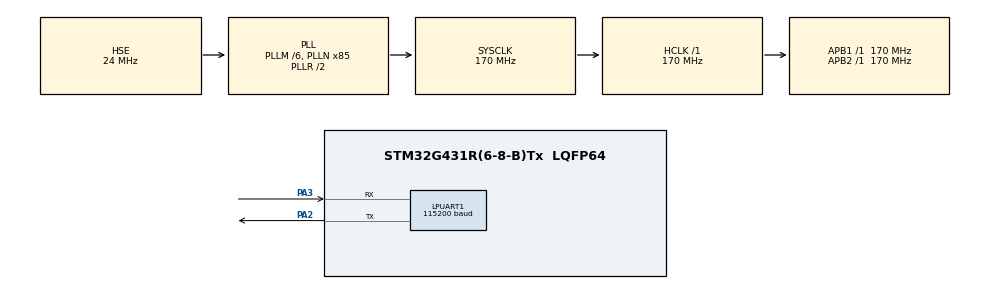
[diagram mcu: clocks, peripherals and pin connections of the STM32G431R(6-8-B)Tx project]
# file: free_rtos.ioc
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FREERTOS.Tasks01=defaultTask,0,128,StartDefaultTask,Default,NULL,Dynamic,NULL,NULL
FREERTOS.configENABLE_FPU=1
FREERTOS.configMAX_PRIORITIES=31
FREERTOS.configTOTAL_HEAP_SIZE=10240
FREERTOS.configUSE_NEWLIB_REENTRANT=1
LPUART1.BaudRate=115200
Mcu.Family=STM32G4
Mcu.Name=STM32G431R(6-8-B)Tx
Mcu.Package=LQFP64
NVIC.LPUART1_IRQn=true\:5\:0\:false\:false\:true\:true\:true\:true\:true
NVIC.PriorityGroup=NVIC_PRIORITYGROUP_4
NVIC.TIM1_UP_TIM16_IRQn=true\:15\:0\:false\:false\:true\:false\:false\:true\:true
NVIC.TimeBase=TIM1_UP_TIM16_IRQn
NVIC.TimeBaseIP=TIM1
PA13.Mode=Serial_Wire
PA13.Signal=SYS_JTMS-SWDIO
PA14.Mode=Serial_Wire
PA14.Signal=SYS_JTCK-SWCLK
PA2.Mode=Asynchronous
PA2.Signal=LPUART1_TX
PA3.Mode=Asynchronous
PA3.Signal=LPUART1_RX
PF0-OSC_IN.Mode=HSE-External-Oscillator
PF0-OSC_IN.Signal=RCC_OSC_IN
PF1-OSC_OUT.Mode=HSE-External-Oscillator
PF1-OSC_OUT.Signal=RCC_OSC_OUT
ProjectManager.HeapSize=0x200
ProjectManager.StackSize=0x400
ProjectManager.TargetToolchain=STM32CubeIDE
RCC.ADC12Freq_Value=170000000
RCC.AHBFreq_Value=170000000
RCC.APB1Freq_Value=170000000
RCC.APB1TimFreq_Value=170000000
RCC.APB2Freq_Value=170000000
RCC.APB2TimFreq_Value=170000000
RCC.CortexFreq_Value=170000000
RCC.EXTERNAL_CLOCK_VALUE=12288000
RCC.HCLKFreq_Value=170000000
RCC.HSE_VALUE=24000000
RCC.HSI48_VALUE=48000000
RCC.HSI_VALUE=16000000
RCC.LSE_VALUE=32768
RCC.PLLM=RCC_PLLM_DIV6
RCC.PLLN=85
RCC.PLLSourceVirtual=RCC_PLLSOURCE_HSE
RCC.SYSCLKFreq_VALUE=170000000
RCC.SYSCLKSource=RCC_SYSCLKSOURCE_PLLCLK
RCC.USBFreq_Value=170000000
RCC.VCOOutputFreq_Value=340000000
VP_FREERTOS_VS_CMSIS_V1.Mode=CMSIS_V1
VP_SYS_VS_tim1.Mode=TIM1
board=custom

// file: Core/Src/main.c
/* USER CODE BEGIN Header */
/**
  ******************************************************************************
  * @file           : main.c
  * @brief          : Main program body
  ******************************************************************************
  * @attention
  *
  * Copyright (c) 2023 STMicroelectronics.
  * All rights reserved.
  *
  * This software is licensed under terms that can be found in the LICENSE file
  * in the root directory of this software component.
  * If no LICENSE file comes with this software, it is provided AS-IS.
  *
  ******************************************************************************
  */
/* USER CODE END Header */
#include "main.h"
#include "cmsis_os.h"

UART_HandleTypeDef hlpuart1;

osThreadId defaultTaskHandle;

void SystemClock_Config(void);
static void MX_GPIO_Init(void);
static void MX_LPUART1_UART_Init(void);
void StartDefaultTask(void const * argument);

/* USER CODE BEGIN PFP */
SemaphoreHandle_t LPUARTMutex;
/* USER CODE END PFP */

/* USER CODE BEGIN 0 */

static void serialTask1(void *param) {
	uint32_t count = 0;

	for(;;) {
		if(xSemaphoreTake(LPUARTMutex, portMAX_DELAY) == pdTRUE) {
			HAL_UART_Transmit_IT(&hlpuart1, (uint8_t *)"Teste de Serial 1\n\r", 19);
			xSemaphoreGive(LPUARTMutex);
			count++;
		}

		portYIELD();
	}
}

static void serialTask2(void *param) {
	uint32_t count = 0;

	for(;;) {
		if(xSemaphoreTake(LPUARTMutex, portMAX_DELAY) == pdTRUE) {
			HAL_UART_Transmit_IT(&hlpuart1, (uint8_t *)"Teste de Serial 2\n\r", 19);
			xSemaphoreGive(LPUARTMutex);
			count++;
		}

		portYIELD();
	}
}

static void CPURemain(void *param) {
	uint32_t count = 0;

	for(;;) {
		count++;
	}
}

/* USER CODE END 0 */

int main(void)
{

  /* MCU Configuration--------------------------------------------------------*/

  /* Reset of all peripherals, Initializes the Flash interface and the Systick. */
  HAL_Init();

  /* Configure the system clock */
  SystemClock_Config();

  /* Initialize all configured peripherals */
  MX_GPIO_Init();
  MX_LPUART1_UART_Init();

  /* USER CODE BEGIN RTOS_MUTEX */
  /* add mutexes, ... */
  LPUARTMutex = xSemaphoreCreateMutex();
  /* USER CODE END RTOS_MUTEX */

  /* Create the thread(s) */
  /* definition and creation of defaultTask */
  osThreadDef(defaultTask, StartDefaultTask, osPriorityNormal, 0, 128);
  defaultTaskHandle = osThreadCreate(osThread(defaultTask), NULL);

  /* USER CODE BEGIN RTOS_THREADS */
  /* add threads, ... */
  xTaskCreate(serialTask1, "Task Serial 1", 256, NULL, 7, NULL);
  xTaskCreate(serialTask2, "Task Serial 2", 256, NULL, 7, NULL);
  xTaskCreate(CPURemain, "Sobra CPU", 256, NULL, 1, NULL);
  /* USER CODE END RTOS_THREADS */

  /* Start scheduler */
  osKernelStart();

  /* We should never get here as control is now taken by the scheduler */
  /* Infinite loop */
  while (1)
  {

  }
}

void SystemClock_Config(void)
{
  RCC_OscInitTypeDef RCC_OscInitStruct = {0};
  RCC_ClkInitTypeDef RCC_ClkInitStruct = {0};

  /** Configure the main internal regulator output voltage
  */
  HAL_PWREx_ControlVoltageScaling(PWR_REGULATOR_VOLTAGE_SCALE1_BOOST);

  /** Initializes the RCC Oscillators according to the specified parameters
  * in the RCC_OscInitTypeDef structure.
  */
  RCC_OscInitStruct.OscillatorType = RCC_OSCILLATORTYPE_HSE;
  RCC_OscInitStruct.HSEState = RCC_HSE_ON;
  RCC_OscInitStruct.PLL.PLLState = RCC_PLL_ON;
  RCC_OscInitStruct.PLL.PLLSource = RCC_PLLSOURCE_HSE;
  RCC_OscInitStruct.PLL.PLLM = RCC_PLLM_DIV6;
  RCC_OscInitStruct.PLL.PLLN = 85;
  RCC_OscInitStruct.PLL.PLLP = RCC_PLLP_DIV2;
  RCC_OscInitStruct.PLL.PLLQ = RCC_PLLQ_DIV2;
  RCC_OscInitStruct.PLL.PLLR = RCC_PLLR_DIV2;
  if (HAL_RCC_OscConfig(&RCC_OscInitStruct) != HAL_OK)
  {
    Error_Handler();
  }

  /** Initializes the CPU, AHB and APB buses clocks
  */
  RCC_ClkInitStruct.ClockType = RCC_CLOCKTYPE_HCLK|RCC_CLOCKTYPE_SYSCLK
                              |RCC_CLOCKTYPE_PCLK1|RCC_CLOCKTYPE_PCLK2;
  RCC_ClkInitStruct.SYSCLKSource = RCC_SYSCLKSOURCE_PLLCLK;
  RCC_ClkInitStruct.AHBCLKDivider = RCC_SYSCLK_DIV1;
  RCC_ClkInitStruct.APB1CLKDivider = RCC_HCLK_DIV1;
  RCC_ClkInitStruct.APB2CLKDivider = RCC_HCLK_DIV1;

  if (HAL_RCC_ClockConfig(&RCC_ClkInitStruct, FLASH_LATENCY_4) != HAL_OK)
  {
    Error_Handler();
  }
}

static void MX_LPUART1_UART_Init(void)
{

  hlpuart1.Instance = LPUART1;
  hlpuart1.Init.BaudRate = 115200;
  hlpuart1.Init.WordLength = UART_WORDLENGTH_8B;
  hlpuart1.Init.StopBits = UART_STOPBITS_1;
  hlpuart1.Init.Parity = UART_PARITY_NONE;
  hlpuart1.Init.Mode = UART_MODE_TX_RX;
  hlpuart1.Init.HwFlowCtl = UART_HWCONTROL_NONE;
  hlpuart1.Init.OneBitSampling = UART_ONE_BIT_SAMPLE_DISABLE;
  hlpuart1.Init.ClockPrescaler = UART_PRESCALER_DIV1;
  hlpuart1.AdvancedInit.AdvFeatureInit = UART_ADVFEATURE_NO_INIT;
  if (HAL_UART_Init(&hlpuart1) != HAL_OK)
  {
    Error_Handler();
  }
  if (HAL_UARTEx_SetTxFifoThreshold(&hlpuart1, UART_TXFIFO_THRESHOLD_1_8) != HAL_OK)
  {
    Error_Handler();
  }
  if (HAL_UARTEx_SetRxFifoThreshold(&hlpuart1, UART_RXFIFO_THRESHOLD_1_8) != HAL_OK)
  {
    Error_Handler();
  }
  if (HAL_UARTEx_DisableFifoMode(&hlpuart1) != HAL_OK)
  {
    Error_Handler();
  }

}

static void MX_GPIO_Init(void)
{

  /* GPIO Ports Clock Enable */
  __HAL_RCC_GPIOF_CLK_ENABLE();
  __HAL_RCC_GPIOA_CLK_ENABLE();

}

void StartDefaultTask(void const * argument)
{
  for(;;)
  {
    osDelay(1);
  }
}

void HAL_TIM_PeriodElapsedCallback(TIM_HandleTypeDef *htim)
{
  if (htim->Instance == TIM1) {
    HAL_IncTick();
  }
  /* USER CODE BEGIN Callback 1 */
  if(HAL_GetTick() >= 1000) {
	HAL_IncTick();
  }
  /* USER CODE END Callback 1 */
}

void Error_Handler(void)
{
  __disable_irq();
  while (1)
  {
  }
}
